VERSION ""

NS_ :

BS_:

BU_: MASTER BRIDGE MOTOR SENSOR GPS DBG

BO_ 103 BRIDGE_NODE: 1 BRIDGE
 SG_ BRIDGE_START_cmd : 0|1@1+ (1,0) [0|1] "" MASTER,MOTOR

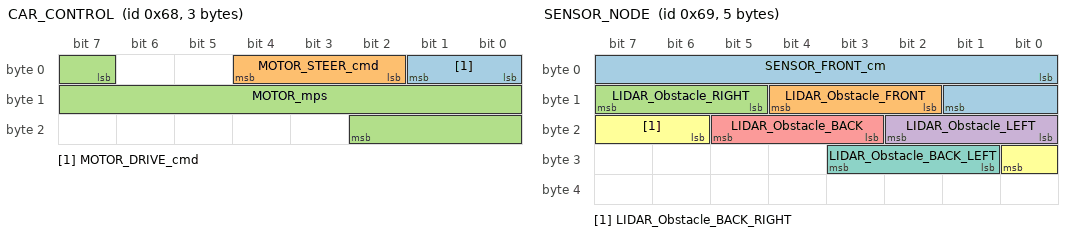
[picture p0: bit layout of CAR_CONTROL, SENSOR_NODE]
BO_ 104 CAR_CONTROL: 3 MASTER
 SG_ MOTOR_DRIVE_cmd : 0|2@1+ (1,0) [0|0] "" MOTOR,BRIDGE
 SG_ MOTOR_STEER_cmd : 2|3@1+ (1,0) [0|0] "" MOTOR,BRIDGE
 SG_ MOTOR_mps : 7|12@1+ (0.01,0) [0.00|20.00] "mps" MOTOR,BRIDGE

BO_ 105 SENSOR_NODE: 5 SENSOR
 SG_ SENSOR_FRONT_cm : 0|10@1+ (1,0) [0|645] "cm" MASTER,MOTOR,BRIDGE
 SG_ LIDAR_Obstacle_FRONT : 10|3@1+ (1,0) [0|0] "" MASTER,MOTOR,BRIDGE
 SG_ LIDAR_Obstacle_RIGHT : 13|3@1+ (1,0) [0|0] "" MASTER,MOTOR,BRIDGE
 SG_ LIDAR_Obstacle_LEFT : 16|3@1+ (1,0) [0|0] "" MASTER,MOTOR,BRIDGE
 SG_ LIDAR_Obstacle_BACK : 19|3@1+ (1,0) [0|0] "" MASTER,MOTOR,BRIDGE
 SG_ LIDAR_Obstacle_BACK_RIGHT : 22|3@1+ (1,0) [0|0] "" MASTER,MOTOR,BRIDGE
 SG_ LIDAR_Obstacle_BACK_LEFT : 25|3@1+ (1,0) [0|0] "" MASTER,MOTOR,BRIDGE

BO_ 106 MOTOR_NODE: 2 MOTOR
 SG_ MOTOR_SPEED_mps : 0|12@1+ (0.01,0) [0.00|20.00] "mps" MASTER,BRIDGE

BO_ 107 BRIDGE_CHECKPOINTS: 8 BRIDGE
 SG_ CHECKPOINT_LAT_deg : 0|28@1+ (0.000001,-90.000000) [-90|90] "Degrees" MASTER,GPS
 SG_ CHECKPOINT_LONG_deg : 28|29@1+ (0.000001,-180.000000) [-180|180] "Degrees" MASTER,GPS

BO_ 108 GPS_LOCATION: 8 GPS
 SG_ CURRENT_LAT_deg : 0|28@1+ (0.000001,-90.000000) [-90|90] "Degrees" MASTER,BRIDGE,MOTOR
 SG_ CURRENT_LONG_deg : 28|29@1+ (0.000001,-180.000000) [-180|180] "Degrees" MASTER,BRIDGE,MOTOR

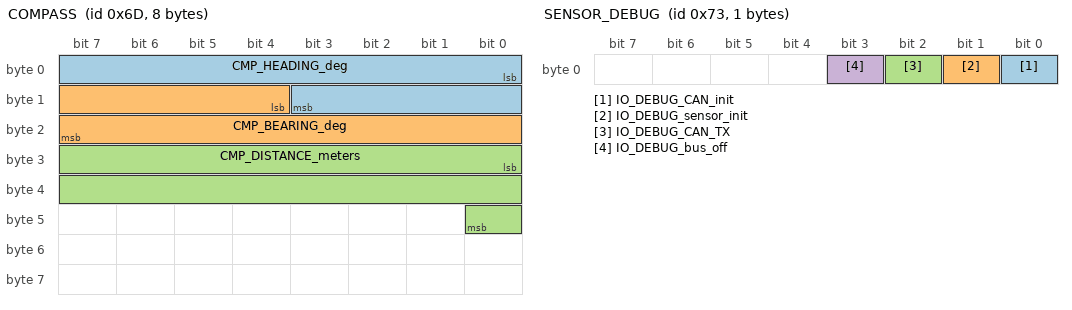
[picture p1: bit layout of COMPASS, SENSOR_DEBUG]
BO_ 109 COMPASS: 8 GPS
 SG_ CMP_HEADING_deg : 0|12@1+ (0.1,0) [0|359.9] "Degrees" MASTER,BRIDGE,MOTOR
 SG_ CMP_BEARING_deg : 12|12@1+ (0.1,0) [0|359.9] "Degrees" MASTER,BRIDGE,MOTOR
 SG_ CMP_DISTANCE_meters : 24|17@1+ (0.001,0) [0|0] "Meters" MASTER,MOTOR,BRIDGE

BO_ 110 MASTER_HEARTBEAT: 1 MASTER
 SG_ MASTER_hbt : 0|1@1+ (1,0) [0|1] "" SENSOR,MOTOR,BRIDGE,GPS

BO_ 111 SENSOR_HEARTBEAT: 1 SENSOR
 SG_ SENSOR_hbt : 0|1@1+ (1,0) [0|1] "" MASTER

BO_ 112 MOTOR_HEARTBEAT: 1 MOTOR
 SG_ MOTOR_hbt : 0|1@1+ (1,0) [0|1] "" MASTER

BO_ 113 GPS_HEARTBEAT: 1 GPS
 SG_ GPS_hbt : 0|1@1+ (1,0) [0|1] "" MASTER

BO_ 114 BRIDGE_HEARTBEAT: 1 BRIDGE
 SG_ BRIDGE_hbt : 0|1@1+ (1,0) [0|1] "" MASTER

BO_ 115 SENSOR_DEBUG: 1 SENSOR
 SG_ IO_DEBUG_CAN_init : 0|1@1+ (1,0) [0|0] "" DBG
 SG_ IO_DEBUG_sensor_init : 1|1@1+ (1,0) [0|0] "" DBG
 SG_ IO_DEBUG_CAN_TX : 2|1@1+ (1,0) [0|0] "" DBG
 SG_ IO_DEBUG_bus_off : 3|1@1+ (1,0) [0|0] "" DBG

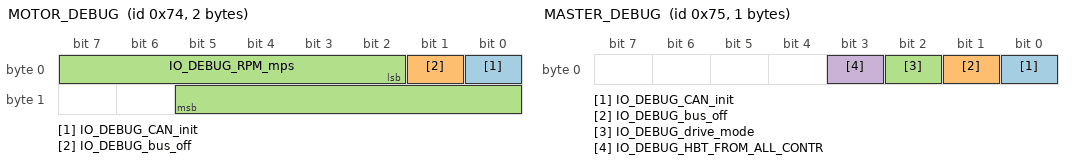
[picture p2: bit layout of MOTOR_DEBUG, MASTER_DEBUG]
BO_ 116 MOTOR_DEBUG: 2 MOTOR
 SG_ IO_DEBUG_CAN_init : 0|1@1+ (1,0) [0|0] "" DBG
 SG_ IO_DEBUG_bus_off : 1|1@1+ (1,0) [0|0] "" DBG
 SG_ IO_DEBUG_RPM_mps : 2|12@1+ (0.01,0) [0.00|20.00] "mps" DBG

BO_ 117 MASTER_DEBUG: 1 MASTER
 SG_ IO_DEBUG_CAN_init : 0|1@1+ (1,0) [0|0] "" DBG
 SG_ IO_DEBUG_bus_off : 1|1@1+ (1,0) [0|0] "" DBG
 SG_ IO_DEBUG_drive_mode : 2|1@1+ (1,0) [0|0] "" DBG
 SG_ IO_DEBUG_HBT_FROM_ALL_CONTR : 3|1@1+ (1,0) [0|0] "" DBG

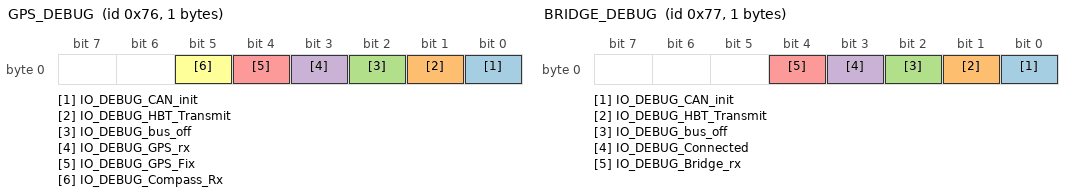
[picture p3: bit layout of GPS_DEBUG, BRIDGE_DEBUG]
BO_ 118 GPS_DEBUG: 1 GPS
 SG_ IO_DEBUG_CAN_init : 0|1@1+ (1,0) [0|0] "" DBG
 SG_ IO_DEBUG_HBT_Transmit : 1|1@1+ (1,0) [0|0] "" DBG
 SG_ IO_DEBUG_bus_off : 2|1@1+ (1,0) [0|0] "" DBG
 SG_ IO_DEBUG_GPS_rx : 3|1@1+ (1,0) [0|0] "" DBG
 SG_ IO_DEBUG_GPS_Fix : 4|1@1+ (1,0) [0|0] "" DBG
 SG_ IO_DEBUG_Compass_Rx : 5|1@1+ (1,0) [0|0] "" DBG

BO_ 119 BRIDGE_DEBUG: 1 BRIDGE
 SG_ IO_DEBUG_CAN_init : 0|1@1+ (1,0) [0|0] "" DBG
 SG_ IO_DEBUG_HBT_Transmit : 1|1@1+ (1,0) [0|0] "" DBG
 SG_ IO_DEBUG_bus_off : 2|1@1+ (1,0) [0|0] "" DBG
 SG_ IO_DEBUG_Connected : 3|1@1+ (1,0) [0|0] "" DBG
 SG_ IO_DEBUG_Bridge_rx : 4|1@1+ (1,0) [0|0] "" DBG

CM_ BU_ MASTER "The master controller driving the car";
CM_ BU_ MOTOR "The motor controller of the car";
CM_ BU_ SENSOR "The sensor controller of the car";
CM_ BU_ BRIDGE "The bridge controller of the car";
CM_ BU_ GPS "The gps controller of the car";
CM_ BU_ DBG "The debug node of the car";
CM_ BO_ 100 "Sync message used to synchronize the controllers";

BA_DEF_ "BusType" STRING ;
BA_DEF_ BO_ "GenMsgCycleTime" INT 0 0;
BA_DEF_ SG_ "FieldType" STRING ;

BA_DEF_DEF_ "BusType" "CAN";
BA_DEF_DEF_ "FieldType" "";
BA_DEF_DEF_ "GenMsgCycleTime" 0;

BA_ "GenMsgCycleTime" BO_ 103 100;
BA_ "GenMsgCycleTime" BO_ 104 100;
BA_ "GenMsgCycleTime" BO_ 105 100;
BA_ "GenMsgCycleTime" BO_ 106 100;
BA_ "GenMsgCycleTime" BO_ 107 100;
BA_ "GenMsgCycleTime" BO_ 108 100;
BA_ "GenMsgCycleTime" BO_ 109 100;
BA_ "GenMsgCycleTime" BO_ 110 100;
BA_ "GenMsgCycleTime" BO_ 111 100;
BA_ "GenMsgCycleTime" BO_ 112 100;
BA_ "GenMsgCycleTime" BO_ 113 100;
BA_ "GenMsgCycleTime" BO_ 114 100;
BA_ "GenMsgCycleTime" BO_ 115 100;
BA_ "GenMsgCycleTime" BO_ 116 100;
BA_ "GenMsgCycleTime" BO_ 117 100;
BA_ "FieldType" SG_ 104 MOTOR_DRIVE_cmd "MOTOR_DRIVE_cmd";
BA_ "FieldType" SG_ 104 MOTOR_STEER_cmd "MOTOR_STEER_cmd";

VAL_ 104 MOTOR_DRIVE_cmd 2 "MOTOR_STOP" 1 "MOTOR_REV" 0 "MOTOR_FORWARD" ;
VAL_ 104 MOTOR_STEER_cmd 2 "MOTOR_DONT_STEER" 1 "MOTOR_STEER_SLIGHT_LEFT" 0 "MOTOR_STEER_FULL_LEFT" 3 "MOTOR_STEER_SLIGHT_RIGHT" 4 "MOTOR_STEER_FULL_RIGHT" ;
